# ESP32C3 register map
File version: 1.0
CPU: RISC-V RV32IMC single-core 1, little endian, no MPU, FPU, 3 interrupt priority bits
Registers are 32-bit, read-write, reset 0x0 unless marked. A register's access mark holds for its fields unless they carry their own. Offsets are from the block's base; [hi:lo] are bit positions; {n}, {i} and the like mark numbered series.

## I2S
Base 0x00000000
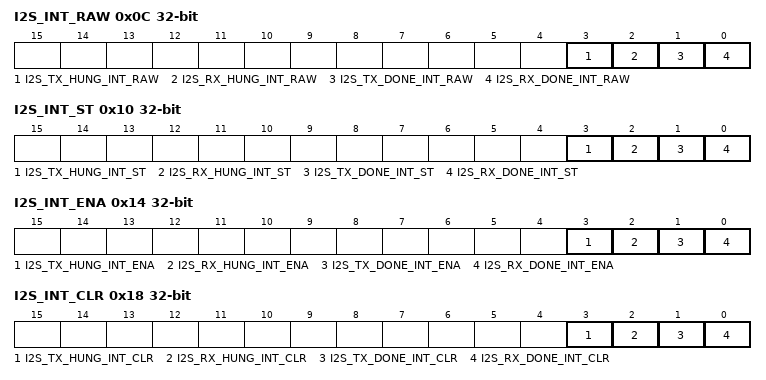
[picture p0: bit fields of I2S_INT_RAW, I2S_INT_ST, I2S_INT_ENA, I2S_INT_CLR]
0x0C I2S_INT_RAW ro
  [3] I2S_TX_HUNG_INT_RAW, [2] I2S_RX_HUNG_INT_RAW, [1] I2S_TX_DONE_INT_RAW, [0] I2S_RX_DONE_INT_RAW
0x10 I2S_INT_ST ro
  [3] I2S_TX_HUNG_INT_ST, [2] I2S_RX_HUNG_INT_ST, [1] I2S_TX_DONE_INT_ST, [0] I2S_RX_DONE_INT_ST
0x14 I2S_INT_ENA
  [3] I2S_TX_HUNG_INT_ENA, [2] I2S_RX_HUNG_INT_ENA, [1] I2S_TX_DONE_INT_ENA, [0] I2S_RX_DONE_INT_ENA
0x18 I2S_INT_CLR wo
  [3] I2S_TX_HUNG_INT_CLR, [2] I2S_RX_HUNG_INT_CLR, [1] I2S_TX_DONE_INT_CLR, [0] I2S_RX_DONE_INT_CLR
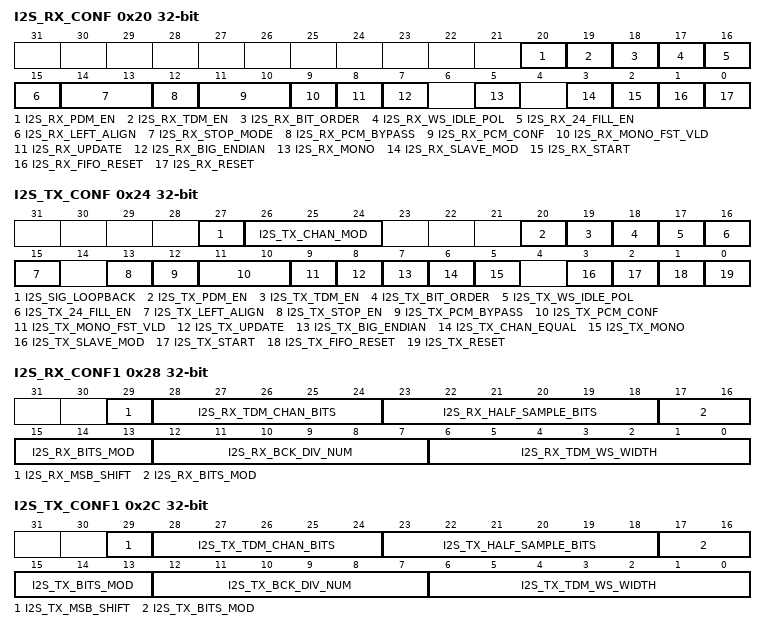
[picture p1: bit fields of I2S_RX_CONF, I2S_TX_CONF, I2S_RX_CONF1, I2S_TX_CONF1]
0x20 I2S_RX_CONF access per field
  [20] I2S_RX_PDM_EN rw, [19] I2S_RX_TDM_EN rw, [18] I2S_RX_BIT_ORDER rw, [17] I2S_RX_WS_IDLE_POL rw, [16] I2S_RX_24_FILL_EN rw, [15] I2S_RX_LEFT_ALIGN rw, [14:13] I2S_RX_STOP_MODE rw, [12] I2S_RX_PCM_BYPASS rw, [11:10] I2S_RX_PCM_CONF rw, [9] I2S_RX_MONO_FST_VLD rw, [8] I2S_RX_UPDATE rw, [7] I2S_RX_BIG_ENDIAN rw, [5] I2S_RX_MONO rw, [3] I2S_RX_SLAVE_MOD rw, [2] I2S_RX_START rw, [1] I2S_RX_FIFO_RESET wo, [0] I2S_RX_RESET wo
0x24 I2S_TX_CONF access per field
  [27] I2S_SIG_LOOPBACK rw, [26:24] I2S_TX_CHAN_MOD rw, [20] I2S_TX_PDM_EN rw, [19] I2S_TX_TDM_EN rw, [18] I2S_TX_BIT_ORDER rw, [17] I2S_TX_WS_IDLE_POL rw, [16] I2S_TX_24_FILL_EN rw, [15] I2S_TX_LEFT_ALIGN rw, [13] I2S_TX_STOP_EN rw, [12] I2S_TX_PCM_BYPASS rw, [11:10] I2S_TX_PCM_CONF rw, [9] I2S_TX_MONO_FST_VLD rw, [8] I2S_TX_UPDATE rw, [7] I2S_TX_BIG_ENDIAN rw, [6] I2S_TX_CHAN_EQUAL rw, [5] I2S_TX_MONO rw, [3] I2S_TX_SLAVE_MOD rw, [2] I2S_TX_START rw, [1] I2S_TX_FIFO_RESET wo, [0] I2S_TX_RESET wo
0x28 I2S_RX_CONF1
  [29] I2S_RX_MSB_SHIFT, [28:24] I2S_RX_TDM_CHAN_BITS, [23:18] I2S_RX_HALF_SAMPLE_BITS, [17:13] I2S_RX_BITS_MOD, [12:7] I2S_RX_BCK_DIV_NUM, [6:0] I2S_RX_TDM_WS_WIDTH
0x2C I2S_TX_CONF1
  [29] I2S_TX_MSB_SHIFT, [28:24] I2S_TX_TDM_CHAN_BITS, [23:18] I2S_TX_HALF_SAMPLE_BITS, [17:13] I2S_TX_BITS_MOD, [12:7] I2S_TX_BCK_DIV_NUM, [6:0] I2S_TX_TDM_WS_WIDTH
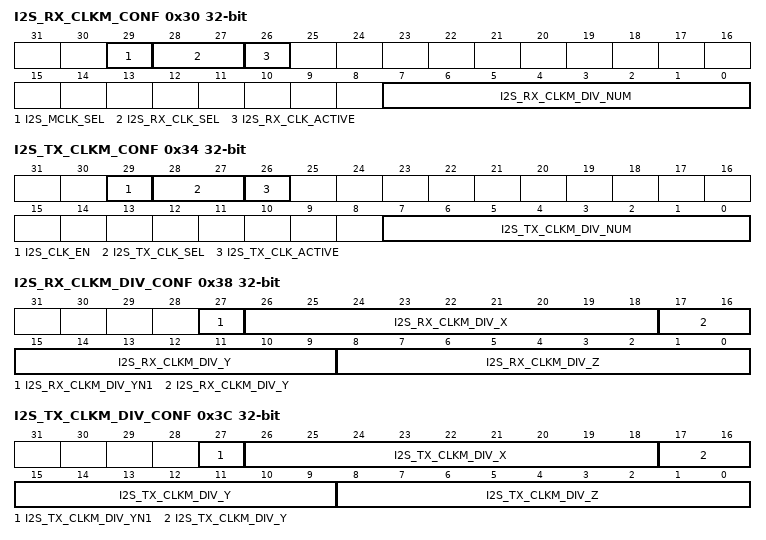
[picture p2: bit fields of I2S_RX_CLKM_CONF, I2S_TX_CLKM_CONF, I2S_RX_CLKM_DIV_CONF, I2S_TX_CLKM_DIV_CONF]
0x30 I2S_RX_CLKM_CONF
  [29] I2S_MCLK_SEL, [28:27] I2S_RX_CLK_SEL, [26] I2S_RX_CLK_ACTIVE, [7:0] I2S_RX_CLKM_DIV_NUM
0x34 I2S_TX_CLKM_CONF
  [29] I2S_CLK_EN, [28:27] I2S_TX_CLK_SEL, [26] I2S_TX_CLK_ACTIVE, [7:0] I2S_TX_CLKM_DIV_NUM
0x38 I2S_RX_CLKM_DIV_CONF
  [27] I2S_RX_CLKM_DIV_YN1, [26:18] I2S_RX_CLKM_DIV_X, [17:9] I2S_RX_CLKM_DIV_Y, [8:0] I2S_RX_CLKM_DIV_Z
0x3C I2S_TX_CLKM_DIV_CONF
  [27] I2S_TX_CLKM_DIV_YN1, [26:18] I2S_TX_CLKM_DIV_X, [17:9] I2S_TX_CLKM_DIV_Y, [8:0] I2S_TX_CLKM_DIV_Z
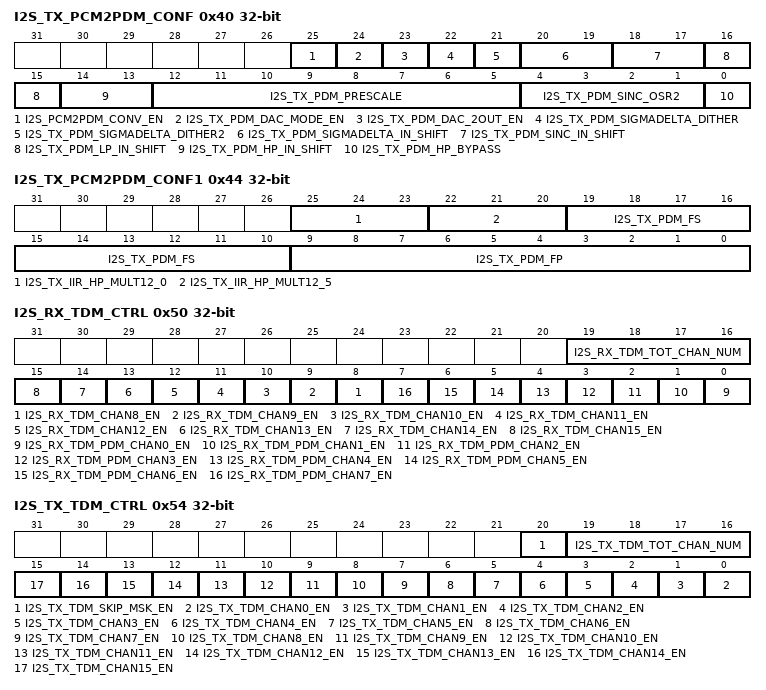
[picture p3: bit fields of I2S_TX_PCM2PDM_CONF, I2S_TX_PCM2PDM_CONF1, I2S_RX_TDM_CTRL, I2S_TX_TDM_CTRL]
0x40 I2S_TX_PCM2PDM_CONF
  [25] I2S_PCM2PDM_CONV_EN, [24] I2S_TX_PDM_DAC_MODE_EN, [23] I2S_TX_PDM_DAC_2OUT_EN, [22] I2S_TX_PDM_SIGMADELTA_DITHER, [21] I2S_TX_PDM_SIGMADELTA_DITHER2, [20:19] I2S_TX_PDM_SIGMADELTA_IN_SHIFT, [18:17] I2S_TX_PDM_SINC_IN_SHIFT, [16:15] I2S_TX_PDM_LP_IN_SHIFT, [14:13] I2S_TX_PDM_HP_IN_SHIFT, [12:5] I2S_TX_PDM_PRESCALE, [4:1] I2S_TX_PDM_SINC_OSR2, [0] I2S_TX_PDM_HP_BYPASS
0x44 I2S_TX_PCM2PDM_CONF1
  [25:23] I2S_TX_IIR_HP_MULT12_0, [22:20] I2S_TX_IIR_HP_MULT12_5, [19:10] I2S_TX_PDM_FS, [9:0] I2S_TX_PDM_FP
0x50 I2S_RX_TDM_CTRL
  [19:16] I2S_RX_TDM_TOT_CHAN_NUM, [n] I2S_RX_TDM_CHAN{n}_EN (n=8..15), [n] I2S_RX_TDM_PDM_CHAN{n}_EN (n=0..7)
0x54 I2S_TX_TDM_CTRL
  [20] I2S_TX_TDM_SKIP_MSK_EN, [19:16] I2S_TX_TDM_TOT_CHAN_NUM, [n] I2S_TX_TDM_CHAN{n}_EN (n=0..15)
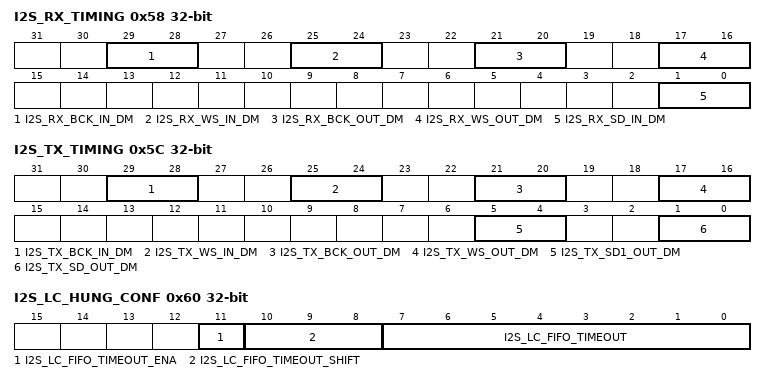
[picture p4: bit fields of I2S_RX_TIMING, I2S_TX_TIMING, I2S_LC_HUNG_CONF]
0x58 I2S_RX_TIMING
  [29:28] I2S_RX_BCK_IN_DM, [25:24] I2S_RX_WS_IN_DM, [21:20] I2S_RX_BCK_OUT_DM, [17:16] I2S_RX_WS_OUT_DM, [1:0] I2S_RX_SD_IN_DM
0x5C I2S_TX_TIMING
  [29:28] I2S_TX_BCK_IN_DM, [25:24] I2S_TX_WS_IN_DM, [21:20] I2S_TX_BCK_OUT_DM, [17:16] I2S_TX_WS_OUT_DM, [5:4] I2S_TX_SD1_OUT_DM, [1:0] I2S_TX_SD_OUT_DM
0x60 I2S_LC_HUNG_CONF
  [11] I2S_LC_FIFO_TIMEOUT_ENA, [10:8] I2S_LC_FIFO_TIMEOUT_SHIFT, [7:0] I2S_LC_FIFO_TIMEOUT
0x64 I2S_RXEOF_NUM
  [11:0] I2S_RX_EOF_NUM
0x68 I2S_CONF_SIGLE_DATA
  [31:0] I2S_SINGLE_DATA
0x6C I2S_STATE ro
  [0] I2S_TX_IDLE
0x80 I2S_DATE
  [27:0] I2S_DATE
